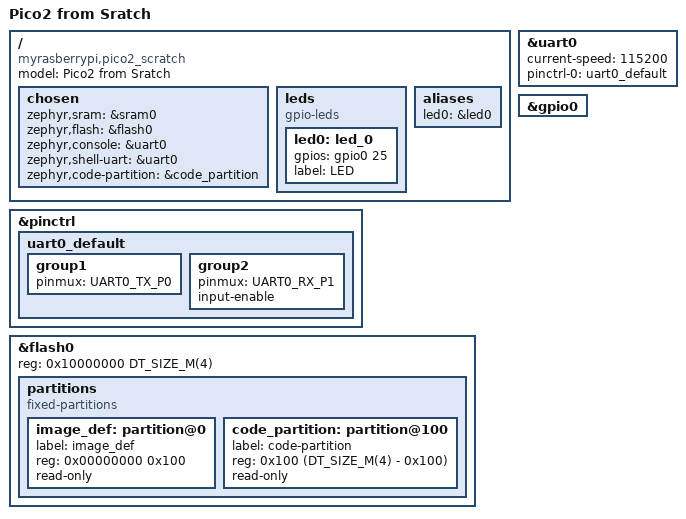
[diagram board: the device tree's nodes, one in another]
/dts-v1/;

/* The build system assumes that there's a cpucluster-specific file.
 *
 * This file provides composition of the device tree:
 * 1. The common features of the SoC
 * 2. Core-specific configuration.
 * 3. Board-specific configuration.
 */
#include <raspberrypi/rpi_pico/rp2350a.dtsi>
#include <raspberrypi/rpi_pico/m33.dtsi>

#include <zephyr/dt-bindings/pinctrl/rpi-pico-rp2350a-pinctrl.h>

/ {
    model = "Pico2 from Sratch";
    compatible = "myrasberrypi,pico2_scratch";

	chosen {
		zephyr,sram = &sram0;
		zephyr,flash = &flash0;
		zephyr,console = &uart0;
		zephyr,shell-uart = &uart0;
		zephyr,code-partition = &code_partition;
	};

    leds {
        compatible = "gpio-leds";
        led0: led_0 {
            gpios = <&gpio0 25 GPIO_ACTIVE_HIGH>;
            label = "LED";
        };
    };

    aliases {
		led0 = &led0;
    };
};

&pinctrl {
    uart0_default: uart0_default {
        group1 {
            pinmux = <UART0_TX_P0>;
        };  
        group2 {
            pinmux = <UART0_RX_P1>;
            input-enable;
        };  
    }; 
};

&flash0 {
	reg = <0x10000000 DT_SIZE_M(4)>;

	partitions {
		compatible = "fixed-partitions";
		#address-cells = <1>;
		#size-cells = <1>;

		/* Reserved memory for an image definition block. The block is much
		 * smaller than 256 bytes, but in practice the linker places the vector
		 * table at a much larger alignment offset.
		 */
		image_def: partition@0 {
			label = "image_def";
			reg = <0x00000000 0x100>;
			read-only;
		};

		/*
		 * Usable flash. Starts at 0x100, after the image definition block.
		 * The partition size is 4MB minus the 0x100 bytes taken by the
		 * image definition.
		 */
		code_partition: partition@100 {
			label = "code-partition";
			reg = <0x100 (DT_SIZE_M(4) - 0x100)>;
			read-only;
		};
	};
};

&uart0 {
	current-speed = <115200>;
	status = "okay";
	pinctrl-0 = <&uart0_default>;
	pinctrl-names = "default";
};

gpio0_lo: &gpio0 {
	status = "okay";
};

pico_serial: &uart0 {};
